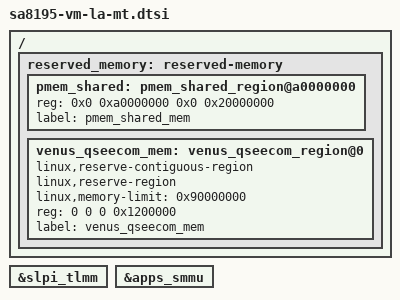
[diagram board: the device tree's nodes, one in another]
/* Copyright (c) 2020, The Linux Foundation. All rights reserved.
 *
 * This program is free software; you can redistribute it and/or modify
 * it under the terms of the GNU General Public License version 2 and
 * only version 2 as published by the Free Software Foundation.
 *
 * This program is distributed in the hope that it will be useful,
 * but WITHOUT ANY WARRANTY; without even the implied warranty of
 * MERCHANTABILITY or FITNESS FOR A PARTICULAR PURPOSE.  See the
 * GNU General Public License for more details.
 */

/ {
	reserved_memory: reserved-memory {

		pmem_shared: pmem_shared_region@a0000000 {
			reg = <0x0 0xa0000000 0x0 0x20000000>;
			label = "pmem_shared_mem";
		};

		venus_qseecom_mem: venus_qseecom_region@0 {
			linux,reserve-contiguous-region;
			linux,reserve-region;
			linux,memory-limit = <0x90000000>;
			reg = <0 0 0 0x1200000>;
			label = "venus_qseecom_mem";
		};
	};

	/delete-node/ cpus;
};

&slpi_tlmm {
	status = "ok";
};

&apps_smmu {
	status = "ok";
};
